# PY32F002Xxx register map
Vendor: Puya; Series: PY32F0; File version: 1.0.0
CPU: CM0+ r0p1, little endian, no MPU, no FPU, 4 interrupt priority bits
Registers are 32-bit, read-write, reset 0x0 unless marked. A register's access mark holds for its fields unless they carry their own. Offsets are from the block's base; [hi:lo] are bit positions; {n}, {i} and the like mark numbered series.

## IWDG — Independent watchdog
Base 0x40003000
0x00 KR wo — Key register (IWDG_KR)
  [15:0] KEY — Key value
0x04 PR — Prescaler register (IWDG_PR)
  [2:0] PR — Prescaler divider
    1=0; 2=1; 4=2
0x08 RLR reset 0xFFF — Reload register (IWDG_RLR)
  [11:0] RL — Watchdog counter reload value
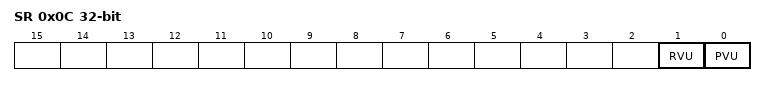
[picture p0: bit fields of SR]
0x0C SR ro — Status register (IWDG_SR)
  [1] RVU — Watchdog counter reload value update
  [0] PVU — Watchdog prescaler value update

## LPTIM1 — Low power timer
Base 0x40007C00
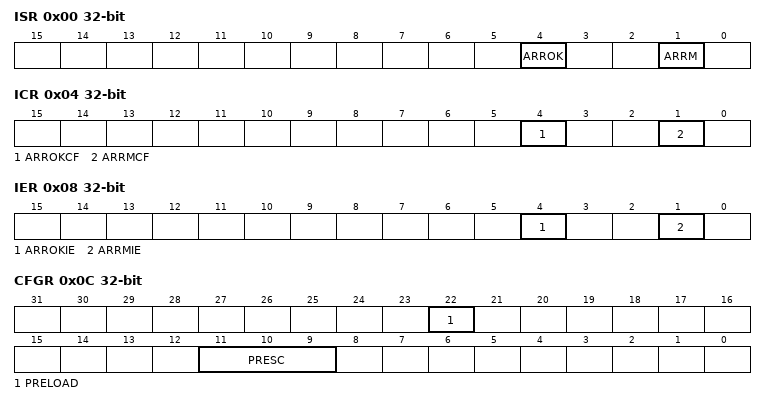
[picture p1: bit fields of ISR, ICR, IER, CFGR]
0x00 ISR ro — Interrupt and Status Register
  [4] ARROK — Autoreload match update OK
  [1] ARRM — Autoreload match
0x04 ICR wo — Interrupt Clear Register
  [4] ARROKCF — Autoreload match update OK Clear Flag
  [1] ARRMCF — Autoreload match Clear Flag
0x08 IER — Interrupt Enable Register
  [4] ARROKIE — Autoreload match update OK Interrupt Enable
  [1] ARRMIE — Autoreload matchInterrupt Enable
0x0C CFGR — Configuration Register
  [22] PRELOAD — Registers update mode
  [11:9] PRESC — Clock prescaler
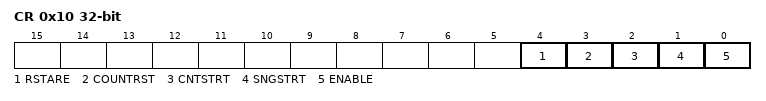
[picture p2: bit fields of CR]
0x10 CR — Control Register
  [4] RSTARE — Reset after read enable
  [3] COUNTRST — Reset counter
  [2] CNTSTRT
  [1] SNGSTRT — LPTIM start in single mode
  [0] ENABLE — LPTIM Enable
0x18 ARR reset 0x1 — Autoreload Register
  [15:0] ARR — Auto reload value
0x1C CNT ro — Counter Register
  [15:0] CNT — Counter value

## PWR — Power control
Base 0x40007000
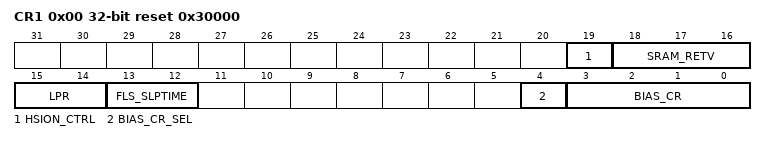
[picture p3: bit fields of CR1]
0x00 CR1 reset 0x30000 — Power control register 1
  [19] HSION_CTRL — HSI open time control
  [18:16] SRAM_RETV — SRAM retention voltage control
  [15:14] LPR — Low-power run
    1=0; 2=1
  [13:12] FLS_SLPTIME — Flash wait time after wakeup from the stop mode
    1=0; 2=1
  [4] BIAS_CR_SEL — MR Bias current selection
  [3:0] BIAS_CR — MR Bias current
    1=0; 2=1; 4=2; 8=3

## SPI1 — Serial peripheral interface
Base 0x40013000
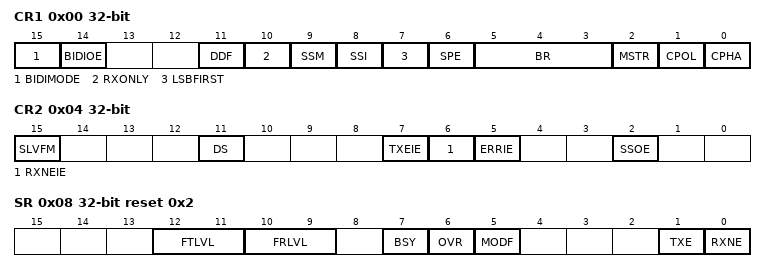
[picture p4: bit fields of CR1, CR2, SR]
0x00 CR1
  [15] BIDIMODE
  [14] BIDIOE
  [11] DDF
  [10] RXONLY
  [9] SSM
  [8] SSI
  [7] LSBFIRST
  [6] SPE
  [5:3] BR
    1=0; 2=1; 4=2
  [2] MSTR
  [1] CPOL
  [0] CPHA
0x04 CR2
  [15] SLVFM, [11] DS, [7] TXEIE, [6] RXNEIE, [5] ERRIE, [2] SSOE
0x08 SR reset 0x2
  [12:11] FTLVL ro, [10:9] FRLVL ro, [7] BSY ro, [6] OVR ro, [5] MODF ro, [1] TXE ro, [0] RXNE ro
0x0C DR
  [15:0] DR

## SYSCFG — System configuration controller
Base 0x40010000
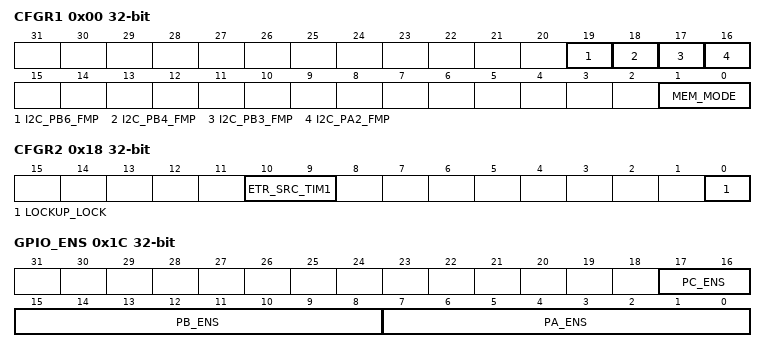
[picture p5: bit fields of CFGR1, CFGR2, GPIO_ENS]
0x00 CFGR1 — SYSCFG configuration register 1
  [19] I2C_PB6_FMP
  [18] I2C_PB4_FMP
  [17] I2C_PB3_FMP
  [16] I2C_PA2_FMP
  [1:0] MEM_MODE — Memory mapping selection bits
    1=0; 2=1
0x18 CFGR2 — SYSCFG configuration register 2
  [10:9] ETR_SRC_TIM1 — TIM1 ETR source selection
    1=0; 2=1
  [0] LOCKUP_LOCK — Cortex-M0+ LOCKUP bit enable bit
0x1C GPIO_ENS
  [17:16] PC_ENS, [15:8] PB_ENS, [7:0] PA_ENS

## TIM1 — Advanced timer
Base 0x40012C00
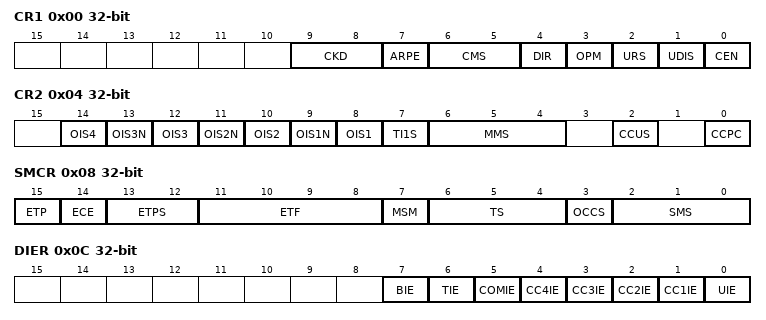
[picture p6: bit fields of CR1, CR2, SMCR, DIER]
0x00 CR1
  [9:8] CKD
    1=0; 2=1
  [7] ARPE
  [6:5] CMS
    1=0; 2=1
  [4] DIR
  [3] OPM
  [2] URS
  [1] UDIS
  [0] CEN
0x04 CR2 (reset mask 0xF8)
  [2n+6] OIS{n} (n=1..4)
  [13] OIS3N
  [11] OIS2N
  [9] OIS1N
  [7] TI1S
  [6:4] MMS
    1=0; 2=1; 4=2
  [2] CCUS
  [0] CCPC
0x08 SMCR (reset mask 0xFFF7)
  [15] ETP
  [14] ECE
  [13:12] ETPS
    1=0; 2=1
  [11:8] ETF
    1=0; 2=1; 4=2; 8=3
  [7] MSM
  [6:4] TS
    1=0; 2=1; 4=2
  [3] OCCS
  [2:0] SMS
    1=0; 2=1; 4=2
0x0C DIER (reset mask 0x5F5F)
  [7] BIE, [6] TIE, [5] COMIE, [n] CC{n}IE (n=1..4), [0] UIE
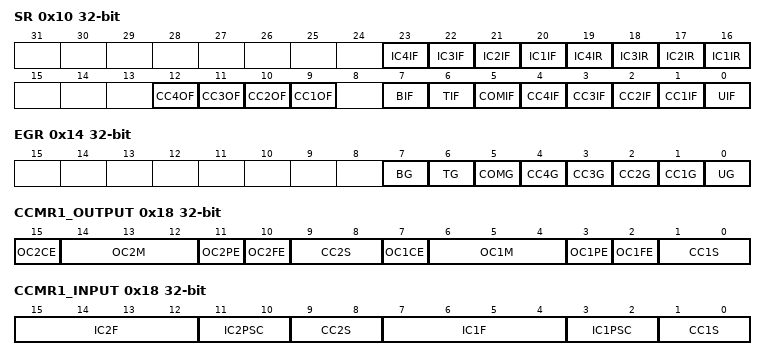
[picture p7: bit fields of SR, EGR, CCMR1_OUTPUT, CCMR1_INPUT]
0x10 SR (reset mask 0x1E5F)
  [23] IC4IF — desc IC3IF
  [22] IC3IF
  [21] IC2IF
  [20] IC1IF
  [19] IC4IR — desc IC3IR
  [18] IC3IR
  [17] IC2IR
  [16] IC1IR
  [n+8] CC{n}OF (n=1..4)
  [7] BIF
  [6] TIF
  [5] COMIF
  [n] CC{n}IF (n=1..4)
  [0] UIF
0x14 EGR wo (reset mask 0x5F)
  [7] BG
  [6] TG
  [5] COMG
  [4] CC4G
  [3] CC3G
  [2] CC2G
  [1] CC1G — Capture/Compare 1 Generation
  [0] UG
0x18 CCMR1_OUTPUT
  [15] OC2CE, [14:12] OC2M, [11] OC2PE, [10] OC2FE, [9:8] CC2S, [7] OC1CE, [6:4] OC1M, [3] OC1PE, [2] OC1FE, [1:0] CC1S
0x18 CCMR1_INPUT (alternate view of CCMR1_OUTPUT)
  [15:12] IC2F, [11:10] IC2PSC, [9:8] CC2S, [7:4] IC1F, [3:2] IC1PSC, [1:0] CC1S
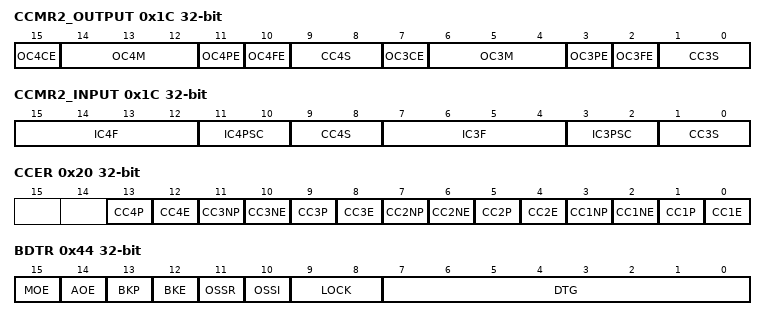
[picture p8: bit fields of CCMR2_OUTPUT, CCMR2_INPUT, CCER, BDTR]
0x1C CCMR2_OUTPUT
  [15] OC4CE, [14:12] OC4M, [11] OC4PE, [10] OC4FE, [9:8] CC4S, [7] OC3CE, [6:4] OC3M, [3] OC3PE, [2] OC3FE, [1:0] CC3S
0x1C CCMR2_INPUT (alternate view of CCMR2_OUTPUT)
  [15:12] IC4F, [11:10] IC4PSC, [9:8] CC4S, [7:4] IC3F, [3:2] IC3PSC, [1:0] CC3S
0x20 CCER (reset mask 0x3333)
  [4n-3] CC{n}P (n=1..4), [4n-4] CC{n}E (n=1..4), [11] CC3NP, [10] CC3NE, [7] CC2NP, [6] CC2NE, [3] CC1NP, [2] CC1NE
0x24 CNT
  [15:0] CNT
0x28 PSC
  [15:0] PSC
0x2C ARR reset 0xFFFF
  [15:0] ARR
0x30 RCR reset 0xFFFF
  [7:0] REP
{0x30+4i} CCR{i} (i=1..4)
  [15:0] CCR{i}
0x44 BDTR
  [15] MOE
  [14] AOE
  [13] BKP
  [12] BKE
  [11] OSSR
  [10] OSSI
  [9:8] LOCK
    1=0; 2=1
  [7:0] DTG
    1=0; 2=1; 4=2; 8=3; 16=4; 32=5; 64=6; 128=7

## TIM14 — General purpose timer
Base 0x40002000
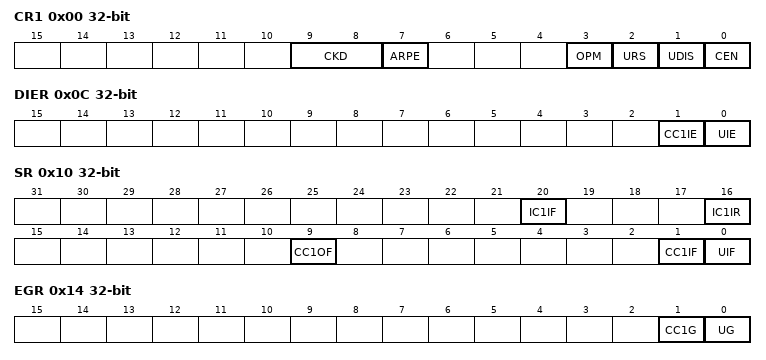
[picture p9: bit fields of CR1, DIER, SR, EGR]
0x00 CR1
  [9:8] CKD
    1=0; 2=1
  [7] ARPE
  [3] OPM
  [2] URS
  [1] UDIS
  [0] CEN
0x0C DIER
  [1] CC1IE, [0] UIE
0x10 SR (reset mask 0x1E5F)
  [20] IC1IF, [16] IC1IR, [9] CC1OF, [1] CC1IF, [0] UIF
0x14 EGR wo
  [1] CC1G — Capture/Compare 1 Generation
  [0] UG
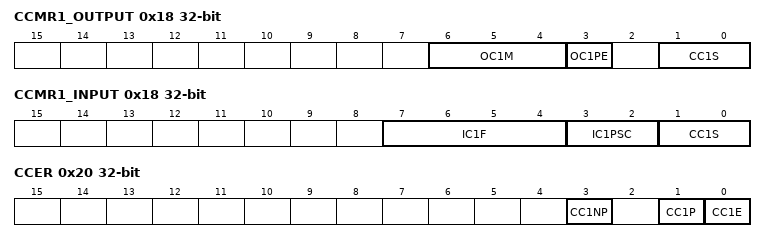
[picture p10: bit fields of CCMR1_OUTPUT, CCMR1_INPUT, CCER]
0x18 CCMR1_OUTPUT
  [6:4] OC1M, [3] OC1PE, [1:0] CC1S
0x18 CCMR1_INPUT (alternate view of CCMR1_OUTPUT)
  [7:4] IC1F, [3:2] IC1PSC, [1:0] CC1S
0x20 CCER (reset mask 0x3333)
  [3] CC1NP, [1] CC1P, [0] CC1E
0x24 CNT
  [15:0] CNT
0x28 PSC
  [15:0] PSC
0x2C ARR reset 0xFFFF
  [15:0] ARR
0x34 CCR1
  [15:0] CCR1
0x50 OR
  [1:0] TI1_RMP
    1=0; 2=1

## USART1 — Universal synchronous asynchronous receiver transmitter
Base 0x40013800
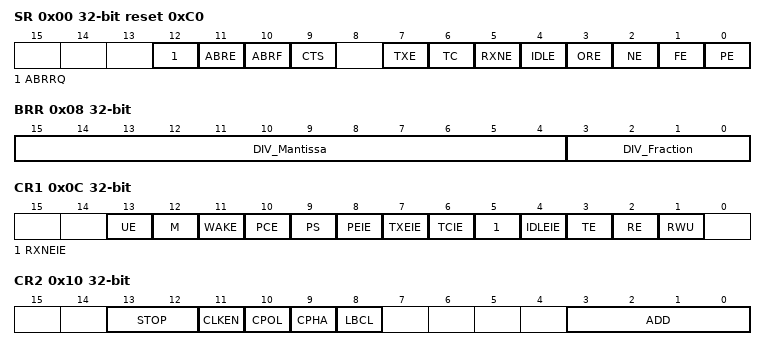
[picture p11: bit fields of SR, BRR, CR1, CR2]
0x00 SR reset 0xC0 — Status register
  [12] ABRRQ wo — Automate baudrate detection requeset
  [11] ABRE ro — Automate baudrate detection error flag
  [10] ABRF ro — Automate baudrate detection flag
  [9] CTS — CTS flag
  [7] TXE ro — Transmit data register empty
  [6] TC — Transmission complete
  [5] RXNE — Read data register not empty
  [4] IDLE ro — IDLE line detected
  [3] ORE ro — Overrun error
  [2] NE ro — Noise error flag
  [1] FE ro — Framing error
  [0] PE ro — Parity error
0x04 DR — Data register
  [8:0] DR — Data value
0x08 BRR — Baud rate register
  [15:4] DIV_Mantissa — mantissa of USARTDIV
  [3:0] DIV_Fraction — fraction of USARTDIV
0x0C CR1 — Control register 1
  [13] UE — USART enable
  [12] M — Word length
  [11] WAKE — Wakeup method
  [10] PCE — Parity control enable
  [9] PS — Parity selection
  [8] PEIE — PE interrupt enable
  [7] TXEIE — TXE interrupt enable
  [6] TCIE — Transmission complete interrupt enable
  [5] RXNEIE — RXNE interrupt enable
  [4] IDLEIE — IDLE interrupt enable
  [3] TE — Transmitter enable
  [2] RE — Receiver enable
  [1] RWU — Receiver wakeup
0x10 CR2 — Control register 2
  [13:12] STOP — STOP bits
  [11] CLKEN — Clock enable
  [10] CPOL — Clock polarity
  [9] CPHA — Clock phase
  [8] LBCL — Last bit clock pulse
  [3:0] ADD — Address of the USART node
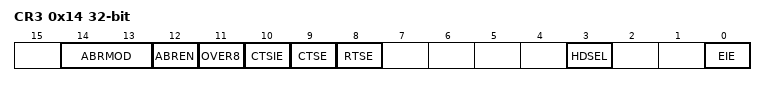
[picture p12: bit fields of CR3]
0x14 CR3 — Control register 3
  [14:13] ABRMOD — Auto baudrate mode
  [12] ABREN — Auto baudrate enable
  [11] OVER8 — Oversampling mode
  [10] CTSIE — CTS interrupt enable
  [9] CTSE — CTS enable
  [8] RTSE — RTS enable
  [3] HDSEL — Half-duplex selection
  [0] EIE — Error interrupt enable
